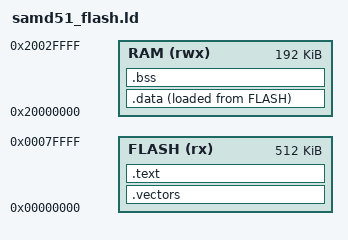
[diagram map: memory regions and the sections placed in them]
MEMORY
{
    FLASH (rx)  : ORIGIN = 0x00000000, LENGTH = 512K
    RAM   (rwx) : ORIGIN = 0x20000000, LENGTH = 192K
}

ENTRY(Reset_Handler)

SECTIONS
{
    .vectors : {
        KEEP(*(.vectors))
    } > FLASH

    .text : {
        *(.text*)
        *(.rodata*)
    } > FLASH

    .data : {
        *(.data*)
    } > RAM AT > FLASH

    .bss : {
        *(.bss*)
        *(COMMON)
    } > RAM
}
